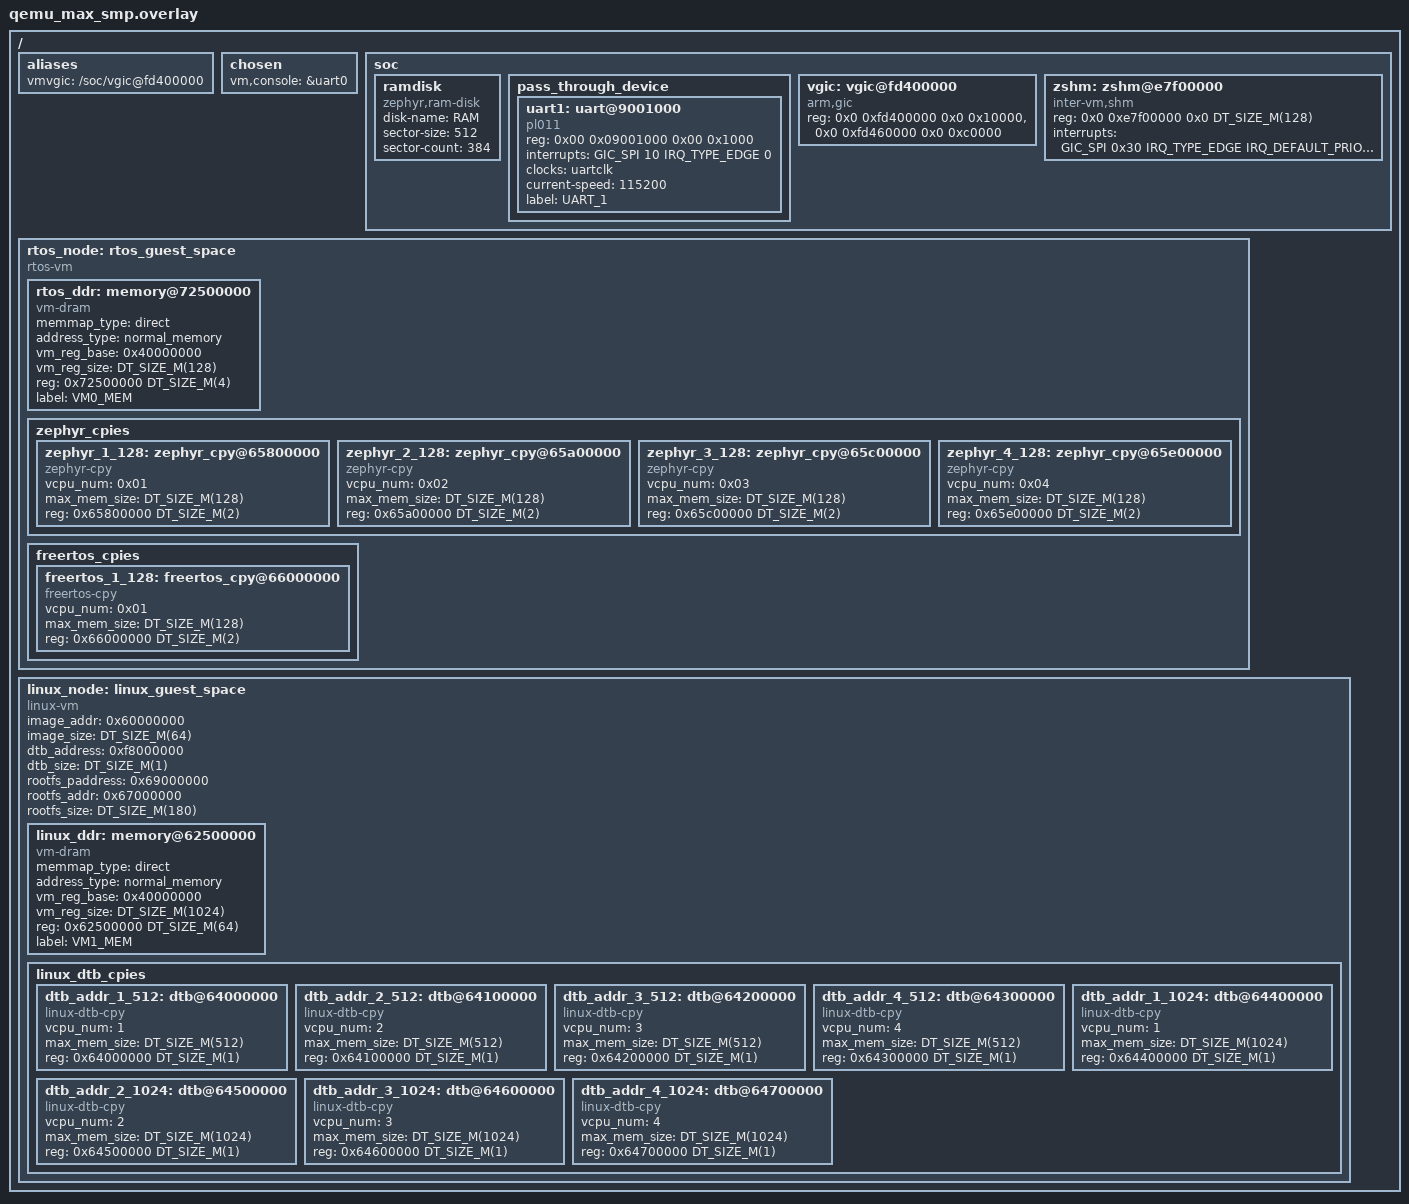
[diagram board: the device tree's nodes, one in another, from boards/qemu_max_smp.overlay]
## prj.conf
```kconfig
# Copyright 2024-2025 HNU-ESNL: Guoqi Xie, Chenglai Xiong, Xingyu Hu and etc.
# Copyright 2024-2025 openEuler SIG-Zephyr
# SPDX-License-Identifier: Apache-2.0

# ZVM
CONFIG_ZVM=y
CONFIG_ZVM_DEBUG_LOG_INFO=y
CONFIG_ZVM_SMP_DEBUG_INFO=n
CONFIG_MAX_VM_NUM=10
CONFIG_MAX_VCPU_PER_VM=4
CONFIG_VM_DTB_FILE_INPUT=y
CONFIG_KERNEL_BIN_NAME="zvm_host"

# console
CONFIG_CONSOLE=y
CONFIG_CONSOLE_SUBSYS=y
CONFIG_CONSOLE_GETLINE=y
CONFIG_UART_CONSOLE=y
CONFIG_SHELL_BACKEND_SERIAL_RX_RING_BUFFER_SIZE=4096
# log
CONFIG_LOG=y
CONFIG_LOG_MODE_MINIMAL=y
CONFIG_LOG_MODE_IMMEDIATE=y
CONFIG_ASSERT=y

# c lib
CONFIG_MINIMAL_LIBC=y
CONFIG_MINIMAL_LIBC_RAND=y
CONFIG_MINIMAL_LIBC_NON_REENTRANT_FUNCTIONS=y
CONFIG_COMMON_LIBC_MALLOC_ARENA_SIZE=4096
CONFIG_GETOPT_LONG=y
CONFIG_POSIX_C_LIB_EXT=y

#shell
CONFIG_SHELL=y
CONFIG_SHELL_GETOPT=y
CONFIG_SHELL_THREAD_PRIORITY_OVERRIDE=y
CONFIG_SHELL_THREAD_PRIORITY=4
CONFIG_SHELL_PROMPT_UART="zvm_host:~#"

CONFIG_SHELL_CMD_BUFF_SIZE=1024
CONFIG_SHELL_PRINTF_BUFF_SIZE=1024
CONFIG_SHELL_STACK_SIZE=10240

#size
CONFIG_PRINTK_BUFFER_SIZE=1024
CONFIG_ISR_STACK_SIZE=40960
CONFIG_SYSTEM_WORKQUEUE_STACK_SIZE=8192
CONFIG_PRIVILEGED_STACK_SIZE=8192

CONFIG_MAIN_STACK_SIZE=20480
CONFIG_IDLE_STACK_SIZE=8192

# 64MB heap size.
CONFIG_HEAP_MEM_POOL_SIZE=267108864

CONFIG_THREAD_NAME=y
CONFIG_THREAD_STACK_INFO=y
CONFIG_SCHED_CPU_MASK=y
CONFIG_SCHED_CPU_MASK_PIN_ONLY=y
CONFIG_NUM_PREEMPT_PRIORITIES=15
CONFIG_TIMING_FUNCTIONS=y
CONFIG_SCHED_DEADLINE=y
CONFIG_NO_OPTIMIZATIONS=y
CONFIG_DYNAMIC_INTERRUPTS=y

CONFIG_MAX_XLAT_TABLES=20480
CONFIG_MAX_DOMAIN_PARTITIONS=32

CONFIG_ZSHM=y

#vcpu
CONFIG_ZVM_VCPU_MULTI=y
CONFIG_VCPU_MIGRATING_INFO=n

CONFIG_ZVM_CLIENT=n
CONFIG_ZVM_MEMORY_RECORDER=n
CONFIG_ZVM_OPERATION_TEST=n

CONFIG_HEARTBEAT=n

# cpu usage
CONFIG_SCHED_THREAD_USAGE=y
CONFIG_SCHED_THREAD_USAGE_ALL=y
CONFIG_SCHED_THREAD_USAGE_ANALYSIS=y
CONFIG_THREAD_RUNTIME_STATS=y
```

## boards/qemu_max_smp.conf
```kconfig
# Copyright 2024-2025 HNU-ESNL: Guoqi Xie, Chenglai Xiong, Xingyu Hu and etc.
# Copyright 2024-2025 openEuler SIG-Zephyr
# SPDX-License-Identifier: Apache-2.0

# hypervisor need 1024M of virtual space.
CONFIG_KERNEL_VM_SIZE=0xC0000000

# virtual device.
CONFIG_VM_VGICV3=y
CONFIG_VM_VSERIAL=y

CONFIG_TIMESLICE_SIZE=20

# RAM Disk
CONFIG_DISK_ACCESS=y
CONFIG_DISK_DRIVERS=y
CONFIG_DISK_DRIVER_RAM=y
```

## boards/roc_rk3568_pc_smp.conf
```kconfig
# Project configuration
# Copyright 2021-2022 HNU


# kernel vm size(1024M virt ram start + size)
# 1024 - 64M Mbit
CONFIG_KERNEL_VM_SIZE=0xC0000000

# vgic device.
CONFIG_VM_VGICV3=y

# vuart device.
CONFIG_VM_VSERIAL=y

# syscon device
CONFIG_VM_SYSCON_CONTROLLER=y

# fiq debugger
CONFIG_VM_FIQ_DEBUGGER=n
CONFIG_VM_CLOCK_SYSTEM_CONTROLLER=y

#Virt IO
CONFIG_VM_VIRTIO_MMIO=y
CONFIG_VM_VIRTIO_BLK=y
CONFIG_VM_VIRTIO_NET=y
# sd
CONFIG_DISK_ACCESS=y
CONFIG_ROCKCHIP_SDHC=y
CONFIG_DISK_DRIVER_SDMMC=y
CONFIG_DISK_DRIVERS=y
CONFIG_SDMMC_SUBSYS=y
CONFIG_SDMMC_STACK=y
CONFIG_MAIN_STACK_SIZE=8192

CONFIG_TIMESLICE_SIZE=20
```

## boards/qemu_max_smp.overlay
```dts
/*
 * Copyright 2024-2025 HNU-ESNL: Guoqi Xie, Chenglai Xiong, Xingyu Hu and etc.
 * Copyright 2024-2025 openEuler SIG-Zephyr
 *
 * SPDX-License-Identifier: Apache-2.0
 */

/{
	aliases {
        vmvgic = "/soc/vgic@fd400000";
	};

    chosen {
		vm,console = &uart0;
	};

    soc {

        ramdisk {
            compatible = "zephyr,ram-disk";
            disk-name = "RAM";
            sector-size = <512>;
            sector-count = <384>;
	    };

        pass_through_device {

            #address-cells = <2>;
            #size-cells = <2>;
            ranges;
            /* using pt device for vm */

            uart1: uart@9001000 {
                compatible = "pl011";
                reg = <0x00 0x09001000 0x00 0x1000>;
                interrupts = <GIC_SPI 10 IRQ_TYPE_EDGE 0>;
                interrupt-names = "irq_0";
                clocks = <&uartclk>;
                status = "okay";
                current-speed = <115200>;
                label = "UART_1";
            };
        };

        vgic: vgic@fd400000 {
            compatible = "arm,gic";
            reg = <0x0 0xfd400000 0x0 0x10000>,
                <0x0 0xfd460000 0x0 0xc0000>;
        };

        zshm: zshm@e7f00000 {
            compatible = "inter-vm,shm";
            reg = <0x0 0xe7f00000 0x0 DT_SIZE_M(128)>;
            interrupts = <GIC_SPI 0x30 IRQ_TYPE_EDGE IRQ_DEFAULT_PRIORITY>;
            device_type = "ZSHM";
        };

    };

    rtos_node: rtos_guest_space {
        #address-cells = <1>;
        #size-cells = <1>;
        compatible = "rtos-vm";

        rtos_ddr: memory@72500000 {
            compatible = "vm-dram";
            memmap_type = "direct";
            address_type = "normal_memory";
            vm_reg_base = <0x40000000>;
            vm_reg_size = <DT_SIZE_M(128)>;
            reg = <0x72500000 DT_SIZE_M(4)>;
            label = "VM0_MEM";
        };

        zephyr_cpies {
            #address-cells = <1>;
            #size-cells = <1>;
            zephyr_1_128: zephyr_cpy@65800000 {
                compatible = "zephyr-cpy";
                vcpu_num = <0x01>;
                max_mem_size = <DT_SIZE_M(128)>;
                reg = <0x65800000 DT_SIZE_M(2)>;
            };
            zephyr_2_128: zephyr_cpy@65a00000 {
                compatible = "zephyr-cpy";
                vcpu_num = <0x02>;
                max_mem_size = <DT_SIZE_M(128)>;
                reg = <0x65a00000 DT_SIZE_M(2)>;
            };
            zephyr_3_128: zephyr_cpy@65c00000 {
                compatible = "zephyr-cpy";
                vcpu_num = <0x03>;
                max_mem_size = <DT_SIZE_M(128)>;
                reg = <0x65c00000 DT_SIZE_M(2)>;
            };
            zephyr_4_128: zephyr_cpy@65e00000 {
                compatible = "zephyr-cpy";
                vcpu_num = <0x04>;
                max_mem_size = <DT_SIZE_M(128)>;
                reg = <0x65e00000 DT_SIZE_M(2)>;
            };
            /* the max addr is 0x67000000 */
        };

        freertos_cpies {

            #address-cells = <1>;
            #size-cells = <1>;
            freertos_1_128: freertos_cpy@66000000 {
                compatible = "freertos-cpy";
                vcpu_num = <0x01>;
                max_mem_size = <DT_SIZE_M(128)>;
                reg = <0x66000000 DT_SIZE_M(2)>;
            };
        };
    };

    linux_node: linux_guest_space {
        #address-cells = <1>;
        #size-cells = <1>;
        compatible = "linux-vm";

        image_addr = <0x60000000>;
        image_size = <DT_SIZE_M(64)>;

        dtb_address = <0xf8000000>;
        dtb_size = <DT_SIZE_M(1)>;

        rootfs_paddress = <0x69000000>;
        rootfs_addr = <0x67000000>;
        rootfs_size = <DT_SIZE_M(180)>;

        linux_ddr: memory@62500000 {
            compatible = "vm-dram";
            memmap_type = "direct";
            address_type = "normal_memory";
            vm_reg_base = <0x40000000>;
            vm_reg_size = <DT_SIZE_M(1024)>;
            reg = <0x62500000 DT_SIZE_M(64)>;
            label = "VM1_MEM";
        };

        linux_dtb_cpies {
            #address-cells = <1>;
            #size-cells = <1>;
            dtb_addr_1_512: dtb@64000000 {
                compatible = "linux-dtb-cpy";
                vcpu_num = <1>;
                max_mem_size = <DT_SIZE_M(512)>;
                reg = <0x64000000 DT_SIZE_M(1)>;
            };
            dtb_addr_2_512: dtb@64100000 {
                compatible = "linux-dtb-cpy";
                vcpu_num = <2>;
                max_mem_size = <DT_SIZE_M(512)>;
                reg = <0x64100000 DT_SIZE_M(1)>;
            };
            dtb_addr_3_512: dtb@64200000 {
                compatible = "linux-dtb-cpy";
                vcpu_num = <3>;
                max_mem_size = <DT_SIZE_M(512)>;
                reg = <0x64200000 DT_SIZE_M(1)>;
            };
            dtb_addr_4_512: dtb@64300000 {
                compatible = "linux-dtb-cpy";
                vcpu_num = <4>;
                max_mem_size = <DT_SIZE_M(512)>;
                reg = <0x64300000 DT_SIZE_M(1)>;
            };
            dtb_addr_1_1024: dtb@64400000 {
                compatible = "linux-dtb-cpy";
                vcpu_num = <1>;
                max_mem_size = <DT_SIZE_M(1024)>;
                reg = <0x64400000 DT_SIZE_M(1)>;
            };
            dtb_addr_2_1024: dtb@64500000 {
                compatible = "linux-dtb-cpy";
                vcpu_num = <2>;
                max_mem_size = <DT_SIZE_M(1024)>;
                reg = <0x64500000 DT_SIZE_M(1)>;
            };
            dtb_addr_3_1024: dtb@64600000 {
                compatible = "linux-dtb-cpy";
                vcpu_num = <3>;
                max_mem_size = <DT_SIZE_M(1024)>;
                reg = <0x64600000 DT_SIZE_M(1)>;
            };
            dtb_addr_4_1024: dtb@64700000 {
                compatible = "linux-dtb-cpy";
                vcpu_num = <4>;
                max_mem_size = <DT_SIZE_M(1024)>;
                reg = <0x64700000 DT_SIZE_M(1)>;
            };
            /* the max addr is 0x65800000*/
        };
    };
};
```

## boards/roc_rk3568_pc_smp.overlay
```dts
/*
 * Copyright 2021-2022 HNU-ESNL
 *
 * SPDX-License-Identifier: Apache-2.0
 */

/{
	aliases {
        vmvgic = "/soc/vgic@fd400000";
		//ptdevice1 = "/soc/ptdev@0/serial@fe660000";
		//ptdevice2 = "/soc/ptdev@0/serial@fe670000";
        ptdevice3 = "/soc/ptdev@0/linuxdev@103000";
        // linuxdebugger = "/soc/fiq-debugger";
        zephyrcpy = "/soc/zephyr_cpy@1000000";
        linuxcpy = "/soc/linux_cpy@4000000";
        linuxdtb = "/soc/linux_dtb@c000000";
        linuxrfs = "/soc/linux_rootfs@e0000000";
        zshm    = "/soc/zshm@b0000000";
	};

	chosen {
		vm,console = &uart2;
        vm,blk = "/soc/ptdev@0/virtio_mmio@a000000";
	};


    soc {

        pass_through_device: ptdev@0 {

            #address-cells = <2>;
            #size-cells = <2>;
            ranges = <0x0 0x0 0x0 0x1 0x0>;
/*
            uart3: serial@fe670000 {
                compatible = "rockchip-ns16550";
                reg = <0x0 0xfe670000 0x0 0x10000>;
                interrupts = <GIC_SPI 119 IRQ_TYPE_EDGE IRQ_DEFAULT_PRIORITY>;
                clock-frequency = <12000000>;
                reg-shift = <2>;
                status = "okay";
                current-speed = <1500000>;
                label = "UART3";
            };

            uart2: serial@fe660000 {
                compatible = "rockchip-ns16550";
                reg = <0x0 0xfe660000 0x0 0x10000>;
                interrupts = <GIC_SPI 118 IRQ_TYPE_EDGE IRQ_DEFAULT_PRIORITY>;
                clock-frequency = <12000000>;
                reg-shift = <2>;
                status = "okay";
                current-speed = <1500000>;
                label = "UART2";
            };
*/
            virtio_mmio@a000000 {
                interrupts = <GIC_SPI 0x10 IRQ_TYPE_EDGE 0>;
                reg = <0x0 0xa000000 0x0 0x1000>;
                compatible = "virtio,mmio";
                device_type = "virtio";
                virtio_type = <2>;
                label = "VIRTIOBLK";
                status = "okay";
            };

            virtio_mmio@a001000 {
                interrupts = <GIC_SPI 0x11 IRQ_TYPE_EDGE 0>;
                reg = <0x0 0xa001000 0x0 0x1000>;
                compatible = "virtio,mmio";
                device_type = "virtio";
                virtio_type = <2>;
                label = "VIRTIOBLK";
                status = "okay";
            };

            linuxdev: linuxdev@103000 {
                compatible = "rockchip,rk3399-i2c";
                reg = <0x0 0x103000 0x0 0x1000>;
                interrupts = <GIC_SPI 150 IRQ_TYPE_EDGE IRQ_DEFAULT_PRIORITY>;
                status = "okay";
                label = "LINUXDEV";
            };

        };

        zshm@b0000000 {
            compatible = "inter-vm,shm";
            reg = <0x0 0xb0000000 0x0 DT_SIZE_M(128)>;
            interrupts = <GIC_SPI 0x30 IRQ_TYPE_EDGE IRQ_DEFAULT_PRIORITY>;
            device_type = "ZSHM";
        };

        vgic: vgic@fd400000 {
            compatible = "gic";
            reg = <0xfd400000 0x10000>,
                  <0xfd460000 0xc0000>;
        };
/*
        // debug_uart: fiq-debugger {
        //     compatible = "rockchip,fiq-debugger";
        //     rockchip,serial-id = <0x02>;
        //     rockchip,wake-irq = <0x00>;
        //     rockchip,irq-mode-enable = <0x01>;
        //     rockchip,baudrate = <1500000>;
        //     interrupts = <GIC_SPI 220 IRQ_TYPE_EDGE IRQ_DEFAULT_PRIORITY>;
        //     status = "okay";
        // };
*/
        zephyr_cpy@1000000 {
            reg = <0x01000000 DT_SIZE_M(2)>;
        };

        linux_cpy@4000000 {
            reg = <0x04000000 DT_SIZE_M(64)>;
        };

        linux_dtb@c000000 {
            reg = <0x0c000000 DT_SIZE_M(2)>;
        };

        linux_rootfs@e0000000 {
            reg = <0xe0000000 DT_SIZE_M(180)>;
        };
    };

    /*TODO: The device that used by vm will be added below. */
    vm_zephyr_space {
        #address-cells = <2>;
        #size-cells = <2>;
        compatible = "zephyr-vm";
        dtb_address = <0x200000>;
        dtb_size = <DT_SIZE_M(2)>;
        vcpu_num = <0x01>;

        zephyr_ddr: memory@30000000 {
            compatible = "vm-dram";
            memmap_type = "dirct";
            address_type = "normal_memory";
            vm_reg_base = <0x40000000>;
            vm_reg_size = <DT_SIZE_M(128)>;
            reg = <0x0 0x30000000 0x0 DT_SIZE_M(4)>;
            label = "VM0_MEM";
        };

    };

    vm_linux_space {
        #address-cells = <2>;
        #size-cells = <2>;
        compatible = "linux-vm";
        dtb_address = <0x99000000>;
        dtb_size = <DT_SIZE_M(2)>;
        vcpu_num = <0x01>;
        rootfs_address = <0x69000000>;

        linux_ddr: memory@60000000 {
            compatible = "vm-dram";
            memmap_type = "dirct";
            address_type = "normal_memory";
            vm_reg_base = <0x40000000>;
            vm_reg_size = <DT_SIZE_M(1024)>;
            reg = <0x0 0x60000000 0x0 DT_SIZE_M(64)>;
            label = "VM1_MEM";
        };
    };

};
```

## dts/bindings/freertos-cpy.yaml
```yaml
description: FreeRTOS Copy

compatible: "freertos-cpy"

properties:
  vcpu_num:
    type: int
    description: |
      Number of virtual CPUs for each FreeRTOS VM (supports SMP).
    required: true
  max_mem_size:
    type: int
    description: |
      Max size of memory region
    required: true
  reg:
    type: array
    required: true
    description: |
      Reg regions for the VM.
```

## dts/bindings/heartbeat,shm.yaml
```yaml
description: shared memory for heartbeat

compatible: "heartbeat,shm"

include: base.yaml

properties:
  device_type:
    type: string
    required: true
```

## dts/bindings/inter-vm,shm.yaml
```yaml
description: inter-vm shared memory

compatible: "inter-vm,shm"

include: base.yaml

properties:
  device_type:
    type: string
    required: true
```

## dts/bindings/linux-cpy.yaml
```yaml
description: Linux Copy

compatible: "linux-cpy"

properties:
  vcpu_num:
    type: int
    description: |
      Number of virtual CPUs for each Linux VM (supports SMP).
    required: true
  max_mem_size:
    type: int
    description: |
      Max size of memory region
    required: true
  reg:
    type: array
    required: true
    description: |
      Reg regions for the VM.

  dtb_addr:
    type: int
    description: |
      Base address of the VM device tree file.
    required: true
  dtb_size:
    type: int
    description: |
      Size of the VM device tree file.
    required: true

  image_addr:
    type: int
    description: |
      Base address of the VM device tree file.
    required: true
  image_size:
    type: int
    description: |
      Size of the VM device tree file.
    required: true

  rootfs_addr:
    type: int
    description: |
      Base address of the VM device tree file.
    required: true
  rootfs_size:
    type: int
    description: |
      Size of the VM device tree file.
    required: true
```

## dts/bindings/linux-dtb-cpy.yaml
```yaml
description: Linux DTB Copy

compatible: "linux-dtb-cpy"

properties:
  vcpu_num:
    type: int
    description: |
      Number of virtual CPUs for each Linux VM (supports SMP).
    required: true
  max_mem_size:
    type: int
    description: |
      Max size of memory region
    required: true
  
  reg:
    type: array
    required: true
    description: |
      Reg regions for the VM.
```

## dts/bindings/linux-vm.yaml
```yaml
description: linux virtual machine space

compatible: "linux-vm"

properties:
  image_addr:
    type: int
    description: |
      Base address of the VM root filesystem.
    required: true

  image_size:
    type: int
    description: |
      Base address of the VM root filesystem.
    required: true

  dtb_address:
    type: int
    description: |
      Base address of the VM device tree file.
    required: true

  dtb_size:
    type: int
    description: |
      Size of the VM device tree file.
    required: true

  rootfs_paddress:
    type: int
    description: |
      Base address of the VM root filesystem.
    required: true

  rootfs_addr:
    type: int
    description: |
      Base address of the VM root filesystem.
    required: true

  rootfs_size:
    type: int
    description: |
      Base address of the VM root filesystem.
    required: true
```

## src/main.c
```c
/*
 * Copyright 2024-2025 HNU-ESNL: Guoqi Xie, Chenglai Xiong, Xingyu Hu and etc.
 * Copyright 2024-2025 openEuler SIG-Zephyr
 *
 * SPDX-License-Identifier: Apache-2.0
 */

#include <zephyr/kernel.h>
#include <zephyr/sys/printk.h>
#include <zephyr/zvm/vm_ops_test.h>
#include <zephyr/zvm/vm_device.h>

static void zvm_print_log(void)
{
	printk("\n \
█████████╗    ██╗     ██╗    ███╗    ███╗  \n \
╚════███╔╝    ██║     ██║    ████╗  ████║  \n \
   ███╔╝      ╚██╗   ██╔╝    ██╔ ████╔██║  \n \
 ██╔╝          ╚██  ██╔╝     ██║ ╚██╔╝██║  \n \
█████████╗      ╚████╔╝      ██║  ╚═╝ ██║  \n \
╚════════╝        ╚═╝        ╚═╝      ╚═╝  \n"
	);
}

#ifdef CONFIG_ZVM_OPERATION_TEST
#define STACK_SIZE 20480
#define THREAD_PRIORITY 5

static K_THREAD_STACK_DEFINE(test_stack, STACK_SIZE);
static struct k_thread test_thread_data;
static void test_thread_entry(void *p1, void *p2, void *p3)
{
	run_all_generated_tests(false, 4, 2);
}
#endif

int main(int argc, char **argv)
{
	zvm_print_log();

#ifdef CONFIG_DISK_DRIVER_SDMMC
	/* Init SDMMC for SD Card*/
	vm_sdmmc_init();
#endif

#ifdef CONFIG_ZVM_OPERATION_TEST
	k_tid_t tid = k_thread_create(
		&test_thread_data, test_stack, STACK_SIZE,
		test_thread_entry, NULL, NULL, NULL,
		THREAD_PRIORITY, 0, K_FOREVER
	);

	/* 绑定到 CPU core 0 */
	k_thread_name_set(tid, "zvm auto test threads");
	k_thread_cpu_mask_clear(tid);          // 清除所有 CPU 绑定
	k_thread_cpu_mask_enable(tid, 0);      // 启用 CPU 0 绑定
	k_thread_start(tid);
#endif
	return 0;
}
```
